# CC2340R5 register map
File version: 1.0
CPU: CM0P 1.0, other endian, MPU, FPU, 3 interrupt priority bits
Registers are 32-bit, read-write, reset 0x0 unless marked. A register's access mark holds for its fields unless they carry their own. Offsets are from the block's base; [hi:lo] are bit positions; 'fields as' and 'values as' point back to an identical list.

## DBGSS
Base 0x4000F000
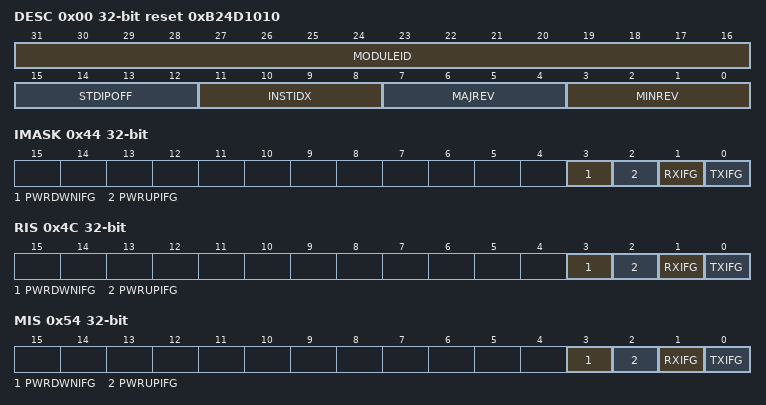
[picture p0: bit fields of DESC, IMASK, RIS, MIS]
0x00 DESC reset 0xB24D1010 — Description Register. This register provides IP module ID, revision information, instance index and standard MMR registers offset.
  [31:16] MODULEID — [31:16] Module identifier used to uniquely identify this IP.
    0xFFFF=MAX (Maximum possible value); 0=MIN (Minimum Value)
  [15:12] STDIPOFF — [15:12] Standard IP MMR block offset. Standard IP MMRs are the set of from aggregated IRQ registers till DTB. 0: Standard IP MMRs do not exist 0x1-0xF: Standard IP MMRs begin at offset of (64*STDIPOFF from the base IP address) 0: STDIP MMRs do not exist 0x1-0xF: These MMRs begin at offset 64*STDIPOFF from IP base address
    15=MAX (Maximum possible value); 0=MIN (Minimum Value)
  [11:8] INSTIDX — [11:8] IP Instance ID number. If multiple instances of IP exist in the device, this field can identify the instance number (0-15).
    15=MAX (Maximum possible value); 0=MIN (Minimum Value)
  [7:4] MAJREV — [7:4] Major revision of IP (0-15).
    15=MAX (Maximum possible value); 0=MIN (Minimum Value)
  [3:0] MINREV — [3:0] Minor revision of IP (0-15).
    15=MAX (Maximum possible value); 0=MIN (Minimum Value)
0x44 IMASK — Interrupt mask. This register selects interrupt sources which are allowed to pass from RIS to MIS when the corresponding bit-fields are set to 1.
  [3] PWRDWNIFG — [3:3] PWRDWNIFG interrupt mask
    1=SET (Interrupt will request an interrupt service routine and corresponding bit in MIS will be set); 0=CLR (Interrupt is masked out)
  [2] PWRUPIFG — [2:2] PWRUPIFG interrupt mask
    values as PWRDWNIFG
  [1] RXIFG — [1:1] RXIFG interrupt mask
    values as PWRDWNIFG
  [0] TXIFG — [0:0] TXIFG interrupt mask
    1=EN (Enable Interrupt Mask); 0=DIS (Disable Interrupt Mask)
0x4C RIS — Raw interrupt status. This register reflects the state of all pending interrupts, regardless of masking. This register allows the user to implement a poll scheme. A flag set in this register can be cleared by writing 1 to the corresponding ICLR register bit.
  [3] PWRDWNIFG — [3:3] Raw interrupt status for PWRDWNIFG
    1=SET (PWRDWNIFG occurred); 0=CLR (PWRDWNIFG did not occur)
  [2] PWRUPIFG — [2:2] Raw interrupt status for PWRUPIFG
    1=SET (PWRUPIFG occurred); 0=CLR (PWRUPIFG did not occur)
  [1] RXIFG — [1:1] Raw interrupt status for RXIFG
    1=SET (RXIFG occurred); 0=CLR (RXIFG did not occur)
  [0] TXIFG — [0:0] Raw interrupt status for TXIFG
    1=SET (TXIFG occurred); 0=CLR (TXIFG did not occur)
0x54 MIS — Masked interrupt status. This register is simply a bitwise AND of the contents of IMASK and RIS.*] registers. A flag set in this register can be cleared by writing 1 to the corresponding ICLR register bit.
  [3] PWRDWNIFG — [3:3] Masked interrupt status for PWRDWNIFG
    1=SET (PWRDWNIFG requests an interrupt service routine); 0=CLR (PWRDWNIFG did not request an interrupt service routine)
  [2] PWRUPIFG — [2:2] Masked interrupt status for PWRUPIFG
    1=SET (PWRUPIFG requests an interrupt service routine); 0=CLR (PWRUPIFG did not request an interrupt service routine)
  [1] RXIFG — [1:1] Masked interrupt status for RXIFG
    1=SET (RXIFG requests an interrupt service routine); 0=CLR (RXIFG did not request an interrupt service routine)
  [0] TXIFG — [0:0] Masked interrupt status for TXIFG
    1=SET (TXIFG requests an interrupt service routine); 0=CLR (TXIFG did not request an interrupt service routine)
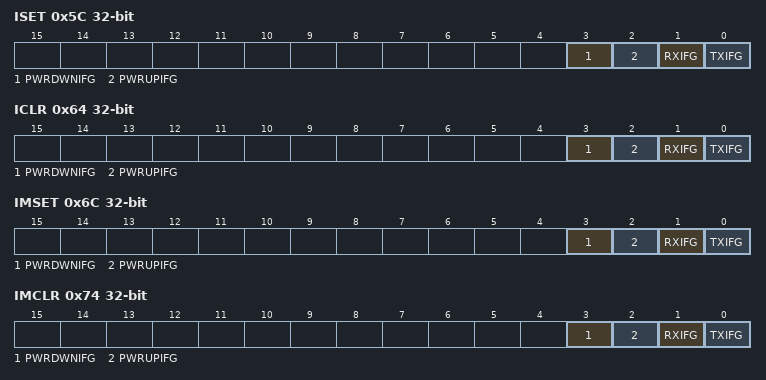
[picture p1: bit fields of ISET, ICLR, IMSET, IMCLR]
0x5C ISET — Interrupt set register. This register can used by software for diagnostics and safety checking purposes. Writing a 1 to a bit in this register will set the event and the corresponding RIS bit also gets set. If the corresponding IMASK bit is set, then the corresponding MIS register bit also gets set.
  [all] fields
    1=SET (Set interrupt); 0=NOEFF (Writing a 0 has no effect)
  [3] PWRDWNIFG — [3:3] Sets PWRDWNIFG in RIS register
  [2] PWRUPIFG — [2:2] Sets PWRUPIFG in RIS register
  [1] RXIFG — [1:1] Sets RXIFG in RIS register
  [0] TXIFG — [0:0] Sets TXIFG in RIS register
0x64 ICLR — Interrupt clear register. This register allows software to clear interrupts. Writing a 1 to a bit in this register will clear the event and the corresponding RIS bit also gets cleared. If the corresponding IMASK bit is set, then the corresponding MIS register bit also gets cleared.
  [all] fields
    1=CLR (Clear interrupt); 0=NOEFF (Writing a 0 has no effect)
  [3] PWRDWNIFG — [3:3] Clears PWRDWNIFG interrupt
  [2] PWRUPIFG — [2:2] Clears PWRUPIFG interrupt
  [1] RXIFG — [1:1] Clears RXIFG interrupt
  [0] TXIFG — [0:0] Clears TXIFG interrupt
0x6C IMSET — Interrupt mask set register. Writing a 1 to a bit in this register will set the corresponding IMASK bit.
  [all] fields
    1=SET (Set interrupt mask); 0=NOEFF (Writing a 0 has no effect)
  [3] PWRDWNIFG — [3:3] Set PWRDWNIFG interrupt mask
  [2] PWRUPIFG — [2:2] Set PWRUPIFG interrupt mask
  [1] RXIFG — [1:1] Set RXIFG interrupt mask
  [0] TXIFG — [0:0] Set TXIFG interrupt mask
0x74 IMCLR — Interrupt mask clear register. Writing a 1 to a bit in this register will clear the corresponding IMASK bit.
  [3] PWRDWNIFG — [3:3] Clears PWRDWNIFG interrupt mask
    1=CLR (IMASK bit corresponding to PWRDWNIFG is cleared); 0=NO_EFFECT (Writing a 0 has no effect)
  [2] PWRUPIFG — [2:2] Clears PWRUPIFG interrupt mask
    1=CLR (IMASK bit corresponding to PWRUPIFG is cleared); 0=NO_EFFECT (Writing a 0 has no effect)
  [1] RXIFG — [1:1] Clears RXIFG interrupt mask
    1=CLR (IMASK bit corresponding to RXIFG is cleared); 0=NO_EFFECT (Writing a 0 has no effect)
  [0] TXIFG — [0:0] Clears TXIFG interrupt mask
    1=CLR (IMASK bit corresponding to TXIFG is cleared); 0=NO_EFFECT (Writing a 0 has no effect)
0x100 TXD — Transmit data register. This register is used for sending SACI command parameter data from the host to the device. The host (SWD interface) can write this register. This updates the value of TXD, and sets TXCTL.TXDSTA = FULL The host should only write TXD while TXCTL.TXDSTA = EMPTY. If the host incorrectly writes TXD while TXCTL.TXDSTA = FULL, this will just update the value of TXD. The host (SWD interface) can read the TXD register. This does not affect TXCTL.TXDSTA. The device (boot code) can only read the TXD register. This sets TXCTL.TXDSTA = EMPTY. The device should only read TXD while TXCTL.TXDSTA = FULL. If the device incorrectly reads TXD while TXCTL.TXDSTA = EMPTY, this will just return the value of TXD. If the host writes TXD on the same clock cycle as the device reads TXD: The device reads the old TXD value. TXD is updated with the new value, and TXCTL.TXDSTA is set to FULL.
  [31:0] VAL ro — [31:0] SACI command/parameter word. Valid value when TXCTL.TXDSTA=1. TXCTL.TXDSTA gets automatically cleared upon read.
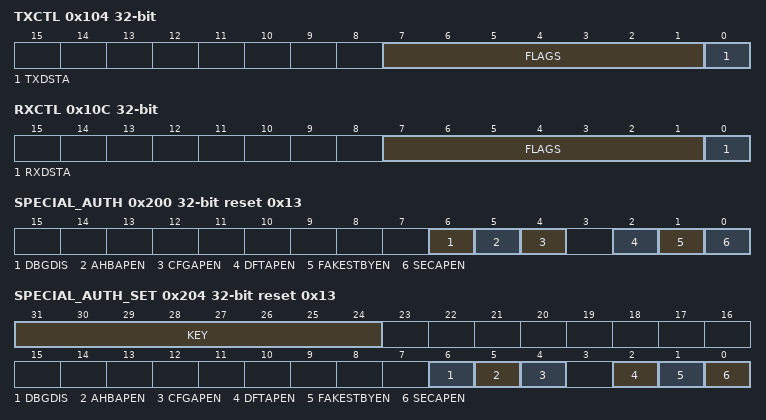
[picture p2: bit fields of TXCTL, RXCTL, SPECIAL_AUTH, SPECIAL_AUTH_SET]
0x104 TXCTL — Transmit control register. This register contains status of the TXD register (full/empty), and also software defined flags that are used by the SACI protocol. The host (SWD interface) can write the FLAGS field of the TXCTL register. The host (SWD interface) can read the TXCTL register. The device (boot code) can only read the TXCTL register.
  [7:1] FLAGS ro — [7:1] Software defined flags that are used by the SACI protocol (host to device).
  [0] TXDSTA ro — [0:0] Indicates whether the host has written a word to the TXD register, which can be read by the device: TXDSTA is automatically set upon write to [SWD_TAP::SECAP.TXD.*] and automatically cleared upon read from TXD
    1=FULL (The TXD register contains a new SACI parameter word from the host, which can be read by the device.); 0=EMPTY (The TXD register does not contain a new SACI parameter word from the host, and should not be read by the device.)
0x108 RXD — Receive data register. This register is used to send SACI command response data from the device to the host. The device (boot code) can write the RXD register. This updates the value of RXD, and sets RXCTL.RXDSTA = FULL. The device should only write RXD while RXCTL.RXDSTA = EMPTY. If the device incorrectly writes RXD while RXCTL.RXDSTA = FULL, this will just update the value of RXD. The device (boot code) can read the RXD register in order to flush it. This sets RXCTL.RXDSTA = EMPTY. The host (SWD interface) can only read the RXD register. This sets RXCTL.RXDSTA = EMPTY. The host should only read RXD while RXCTL.RXDSTA = FULL. If the host incorrectly reads RXD while RXCTL.RXDSTA = EMPTY, this will just return the value of RXD. If the device writes RXD on the same clock cycle as the host reads RXD: The host reads the old RXD value. RXD is updated with the new value, and RXCTL.RXDSTA is set to FULL.
  [31:0] VAL — [31:0] SACI command response word. RXCTL.RXDSTA automatically set upon write. RXCTL.RXDSTA automatically cleared upon read (flush operation).
0x10C RXCTL — Receive control register. This register contains status of the RXD register (full/empty), and also software defined flags that are used by the SACI protocol. The device (boot code) can write the FLAGS field of the RXCTL register. The device (boot code) can read the RXCTL register. The host (SWD interface) can only read the RXCTL register
  [7:1] FLAGS — [7:1] Software defined flags that are used by the SACI protocol (device to host).
  [0] RXDSTA ro — [0:0] Indicates whether the device has written a word to the RXD register, which can be read by the host: RXDSTA is automatically set upon write to RXD and automatically cleared upon read from [SWD_TAP::SECAP.RXD.*] or RXD.
    1=FULL (The RXD register contains a new SACI response word from the device, which can be read by the host.); 0=EMPTY (The RXD register does not contain a new SACI response word from the device, and should not be read by the host.)
0x110 TXDPEEK — Transmit data peek register . This register is a read-only version of the TXD register that can be read by host and device without any side-effects. This register is used to peek at the values in TXD without affecting the FULL/EMPTY flag.
  [31:0] VAL ro — [31:0] Transmit Data Peek Register. SACI command parameter word. TXCTL.TXDSTA not affected by read of TXDPEEK
0x114 RXDPEEK — Receive data peek register. The RXDPEEK register is a read-only version of the RXD register that can be read by host and device without any side-effects This register is used to peek at the values in Receive Data Register without affecting the FULL/EMPTY flag.
  [31:0] VAL ro — [31:0] Receive Data Peek Register. SACI command response word. RXCTL.RXDSTA not affected by read of RXDPEEK
0x200 SPECIAL_AUTH reset 0x13 — This register indicates the status of different AP firewalls and fakestandby enable.
  [6] DBGDIS ro — [6:6] Indicates status of DBGDIS.
    1=DIS (Disables debugging capability); 0=EN (Enables debugging capability.)
  [5] AHBAPEN ro — [5:5] Indicates status of AHBAPEN
    1=EN (Enable AHB-AP); 0=DIS (Disable AHB-AP)
  [4] CFGAPEN ro — [4:4] Indicates status of CFGAPEN
    1=EN (Enable CFG-AP); 0=DIS (Disable CFG-AP)
  [2] DFTAPEN ro — [2:2] Indicates status of DFTAPEN
    1=EN (Enable DFT-TAP); 0=DIS (Disable DFT-TAP)
  [1] FAKESTBYEN ro — [1:1] Indicates status of FAKESTBYEN
    1=EN (FAKESTBYEN is Enabled); 0=DIS (FAKESTBYEN is Disabled)
  [0] SECAPEN ro — [0:0] Indicates status of SECAP
    1=EN (Enable SEC-AP); 0=DIS (Disable SEC-AP)
0x204 SPECIAL_AUTH_SET reset 0x13 — This register is used for setting bits in SPECIAL_AUTH register. This register is configured and locked during device boot.
  [31:24] KEY wo — [31:24] This field must be configured with 0xA5 in order to access this register.
    165=_to_unlock_w_ (This field must be written with 0xA5 to be able to set any of the enable bits)
  [6] DBGDIS wo — [6:6] This bit sets DBGDIS in SPECIAL_AUTH register.
    1=SET (SET DBGDIS); 0=NOEFF (Writing 0 has no effect)
  [5] AHBAPEN wo — [5:5] This bit sets AHBAPEN in SPECIAL_AUTH register.
    1=SET (SET AHB-AP); 0=NOEFF (Writing 0 has no effect)
  [4] CFGAPEN wo — [4:4] This bit sets CFGAPEN in SPECIAL_AUTH register.
    1=SET (Set CFGAPEN); 0=NOEFF (Writing 0 has no effect)
  [2] DFTAPEN wo — [2:2] This bit sets DFTAPEN in SPECIAL_AUTH register.
    1=SET (Set DFTTAPEN); 0=NOEFF (Writing 0 has no effect)
  [1] FAKESTBYEN wo — [1:1] This bit sets FAKESTBYEN in SPECIAL_AUTH register.
    1=SET (Set FAKESTBYEN); 0=NOEFF (Writing 0 has no effect)
  [0] SECAPEN wo — [0:0] This bit sets SECAPEN bit in SPECIAL_AUTH register.
    1=SET (Set SECAPEN); 0=NOEFF (Writing 0 has no effect)
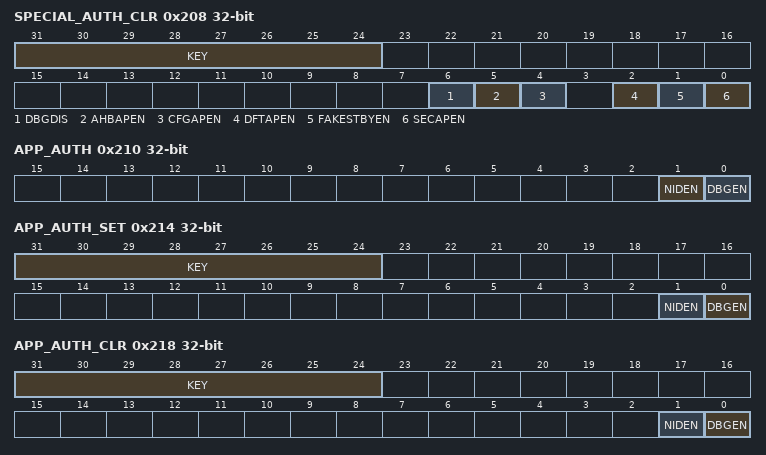
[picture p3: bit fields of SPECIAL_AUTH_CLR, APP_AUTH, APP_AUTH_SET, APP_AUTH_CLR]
0x208 SPECIAL_AUTH_CLR — This register is used for clearing bits in SPECIAL_AUTH register. This register is configured and locked during device boot.
  [31:24] KEY wo — [31:24] This field must be configured with 0x22 in order to access this register.
    34=_to_unlock_w_ (This field must be written with 0x22 to be able to clear any of the enable bits)
  [6] DBGDIS wo — [6:6] This bit clears DBGDIS in SPECIAL_AUTH register.
    1=CLR (Clear DBGDIS); 0=NOEFF (Writing 0 has no effect)
  [5] AHBAPEN wo — [5:5] This bit clears AHBAPEN in SPECIAL_AUTH register.
    1=CLR (Clear AHBAPEN); 0=NOEFF (Writing 0 has no effect)
  [4] CFGAPEN wo — [4:4] This bit clears CFGAPEN in SPECIAL_AUTH register.
    1=CLR (Clear CFGAPEN); 0=NOEFF (Writing 0 has no effect)
  [2] DFTAPEN wo — [2:2] This bit clears DFTTAPEN in SPECIAL_AUTH register.
    1=CLR (Clear DFTTAPEN); 0=NOEFF (Writing 0 has no effect)
  [1] FAKESTBYEN wo — [1:1] This bit clears FAKESTBYEN in SPECIAL_AUTH register.
    1=CLR (Clears FAKESTBYEN); 0=NOEFF (Writing 0 has no effect)
  [0] SECAPEN wo — [0:0] This bit clears SECAPEN in SPECIAL_AUTH register.
    1=CLR (Clear SECAPEN); 0=NOEFF (Writing 0 has no effect)
0x210 APP_AUTH — This register indicates the debug privileges of ARM Cortex CPU.
  [1] NIDEN ro — [1:1] Controls non-invasive debug enable.
    1=EN (Non-invasive debug enabled); 0=DIS (Non-invasive debug disabled)
  [0] DBGEN ro — [0:0] Controls invasive debug enable.
    1=EN (Invasive debug enabled); 0=DIS (Invasive debug disabled)
0x214 APP_AUTH_SET — This register is used for setting bits in APP_AUTH register. This register is configured and locked during device boot.
  [31:24] KEY wo — [31:24] This field must be configured with 0x39 in order to access this register.
    57=_to_unlock_w_ (Write this value 0x39 to unlock writing to the APP_AUTH_SET register)
  [1] NIDEN wo — [1:1] Sets NIDEN bit in [APP_AUTH ]register.
    1=SET (Sets NIDEN); 0=NOEFF (Writing 0 has no effect)
  [0] DBGEN wo — [0:0] Sets DBGEN bit in APP_AUTH register.
    1=SET (Sets DBGEN); 0=NOEFF (Writing 0 has no effect)
0x218 APP_AUTH_CLR — This register is used for clearing bits in APP_AUTH register. This register is configured and locked during device boot.
  [31:24] KEY wo — [31:24] This field must be configured with 0x7D in order to access this register.
    125=_to_unlock_w_ (Write this value 0x7D to unlock writing to the APP_AUTH_CLR register)
  [1] NIDEN wo — [1:1] Clears NIDEN bit in APP_AUTH register.
    1=CLR (Clears NIDEN); 0=NOEFF (Writing 0 has no effect)
  [0] DBGEN wo — [0:0] Clears DBGEN bit in APP_AUTH register.
    1=CLR (Clears DBGEN); 0=NOEFF (Writing 0 has no effect)
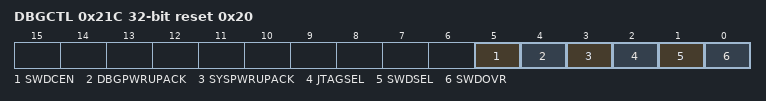
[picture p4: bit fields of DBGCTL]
0x21C DBGCTL reset 0x20 — Debug control register. This register is used for controlling debug connection and read out debug status.
  [5] SWDCEN — [5:5] This bit is used to enable connection between SWD pads and IceMelter
    1=EN (Connection enabled); 0=DIS (Connection disabled)
  [4] DBGPWRUPACK ro — [4:4] This bit field specifies the status of dbgpwrupack from pmctl.
    1=EN (dbgpwrupreq is acknowledged.); 0=DIS (dbgpwrupreq is not acknowledged)
  [3] SYSPWRUPACK ro — [3:3] This bit field specify the status of syspwrupack from pmctl.
    1=EN (syspwrupreq is acknowledged); 0=DIS (syspwrupreq is not acknowledged)
  [2] JTAGSEL ro — [2:2] This bit field specifies the status of JTAG MODE for TEST TAP.
    1=EN (TEST TAP enabled); 0=DIS (TEST TAP disabled)
  [1] SWDSEL ro — [1:1] This bit field specifies the status of SWD MODE for connection.
    1=EN (debug connection enabled.); 0=DIS (debug connection disabled.)
  [0] SWDOVR — [0:0] This bit is used for connecting to IO pads to SWCLK/IO on SW-DP through a software request and establish SWD connection without icemelter trigger for debug purpose.
    1=DBGENA (Force 1 or debug enable mode in which SWD connection is established bypassing ICEMelter sequence); 0=TRNSPRT (Transparent mode in which SWD connection is established via ICEMelter Sequence.)
